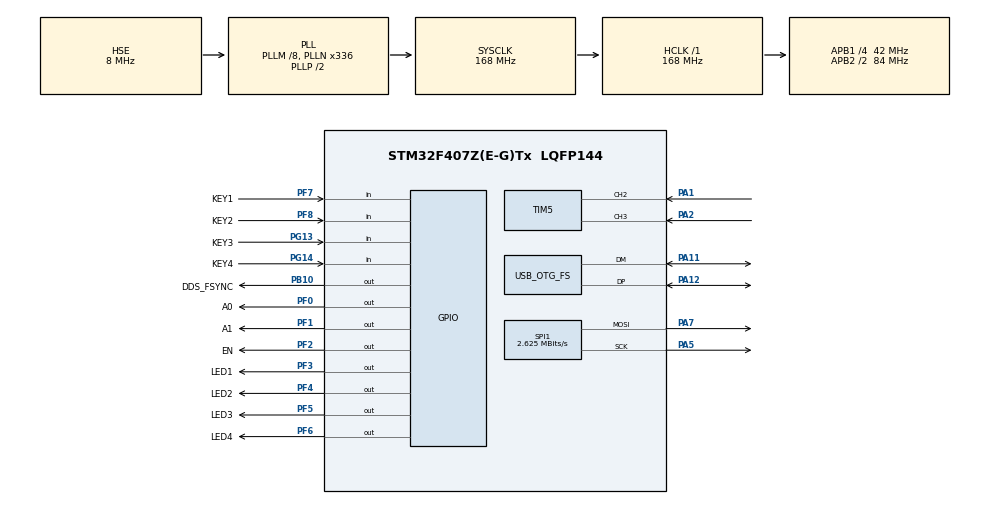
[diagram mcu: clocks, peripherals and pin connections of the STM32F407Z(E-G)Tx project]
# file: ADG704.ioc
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Dma.Request0=TIM5_CH2
Dma.Request1=TIM5_CH3/UP
Dma.TIM5_CH2.0.Direction=DMA_PERIPH_TO_MEMORY
Dma.TIM5_CH2.0.FIFOMode=DMA_FIFOMODE_DISABLE
Dma.TIM5_CH2.0.Instance=DMA1_Stream4
Dma.TIM5_CH2.0.MemDataAlignment=DMA_MDATAALIGN_WORD
Dma.TIM5_CH2.0.MemInc=DMA_MINC_ENABLE
Dma.TIM5_CH2.0.Mode=DMA_NORMAL
Dma.TIM5_CH2.0.PeriphDataAlignment=DMA_PDATAALIGN_WORD
Dma.TIM5_CH2.0.PeriphInc=DMA_PINC_DISABLE
Dma.TIM5_CH2.0.Priority=DMA_PRIORITY_HIGH
Dma.TIM5_CH3/UP.1.Direction=DMA_PERIPH_TO_MEMORY
Dma.TIM5_CH3/UP.1.FIFOMode=DMA_FIFOMODE_DISABLE
Dma.TIM5_CH3/UP.1.Instance=DMA1_Stream0
Dma.TIM5_CH3/UP.1.MemDataAlignment=DMA_MDATAALIGN_WORD
Dma.TIM5_CH3/UP.1.MemInc=DMA_MINC_ENABLE
Dma.TIM5_CH3/UP.1.Mode=DMA_NORMAL
Dma.TIM5_CH3/UP.1.PeriphDataAlignment=DMA_PDATAALIGN_WORD
Dma.TIM5_CH3/UP.1.PeriphInc=DMA_PINC_DISABLE
Dma.TIM5_CH3/UP.1.Priority=DMA_PRIORITY_HIGH
Mcu.Family=STM32F4
Mcu.Name=STM32F407Z(E-G)Tx
Mcu.Package=LQFP144
NVIC.DMA1_Stream0_IRQn=true\:1\:0\:true\:false\:true\:false\:true\:true
NVIC.DMA1_Stream4_IRQn=true\:1\:0\:true\:false\:true\:false\:true\:true
NVIC.PriorityGroup=NVIC_PRIORITYGROUP_4
PA1.Signal=S_TIM5_CH2
PA11.Mode=Device_Only
PA11.Signal=USB_OTG_FS_DM
PA12.Mode=Device_Only
PA12.Signal=USB_OTG_FS_DP
PA13.Signal=SYS_JTMS-SWDIO
PA14.Signal=SYS_JTCK-SWCLK
PA2.Signal=S_TIM5_CH3
PA5.Mode=TX_Only_Simplex_Unidirect_Master
PA5.Signal=SPI1_SCK
PA7.Mode=TX_Only_Simplex_Unidirect_Master
PA7.Signal=SPI1_MOSI
PB10.GPIO_Label=DDS_FSYNC
PB10.GPIO_Speed=GPIO_SPEED_FREQ_HIGH
PB10.PinState=GPIO_PIN_SET
PB10.Signal=GPIO_Output
PF0.GPIO_Label=A0
PF0.GPIO_Speed=GPIO_SPEED_FREQ_LOW
PF0.PinState=GPIO_PIN_RESET
PF0.Signal=GPIO_Output
PF1.GPIO_Label=A1
PF1.Signal=GPIO_Output
PG14.GPIO_Label=KEY4
PG14.Signal=GPIO_Input
PF2.GPIO_Label=EN
PF2.Signal=GPIO_Output
PF3.GPIO_Label=LED1
PF3.Signal=GPIO_Output
PF4.GPIO_Label=LED2
PF4.Signal=GPIO_Output
PF5.GPIO_Label=LED3
PF5.Signal=GPIO_Output
PF6.GPIO_Label=LED4
PF6.Signal=GPIO_Output
PF7.GPIO_Label=KEY1
PF7.GPIO_PuPd=GPIO_NOPULL
PF7.Signal=GPIO_Input
PF8.GPIO_Label=KEY2
PF8.Signal=GPIO_Input
PG13.GPIO_Label=KEY3
PG13.Signal=GPIO_Input
PH0-OSC_IN.Mode=HSE-External-Oscillator
PH0-OSC_IN.Signal=RCC_OSC_IN
PH1-OSC_OUT.Mode=HSE-External-Oscillator
PH1-OSC_OUT.Signal=RCC_OSC_OUT
ProjectManager.HeapSize=0x200
ProjectManager.StackSize=0x400
ProjectManager.TargetToolchain=MDK-ARM V5.32
RCC.48MHZClocksFreq_Value=48000000
RCC.AHBFreq_Value=168000000
RCC.APB1CLKDivider=RCC_HCLK_DIV4
RCC.APB1Freq_Value=42000000
RCC.APB1TimFreq_Value=84000000
RCC.APB2CLKDivider=RCC_HCLK_DIV2
RCC.APB2Freq_Value=84000000
RCC.APB2TimFreq_Value=168000000
RCC.CortexFreq_Value=168000000
RCC.HCLKFreq_Value=168000000
RCC.HSE_VALUE=8000000
RCC.HSI_VALUE=16000000
RCC.LSE_VALUE=32768
RCC.PLLM=8
RCC.PLLN=336
RCC.PLLQ=7
RCC.SYSCLKFreq_VALUE=168000000
RCC.SYSCLKSource=RCC_SYSCLKSOURCE_PLLCLK
RCC.VCOOutputFreq_Value=336000000
SH.S_TIM5_CH2.0=TIM5_CH2,Input_Capture2_from_TI2
SH.S_TIM5_CH3.0=TIM5_CH3,Input_Capture3_from_TI3
SPI1.BaudRatePrescaler=SPI_BAUDRATEPRESCALER_32
SPI1.CLKPolarity=SPI_POLARITY_HIGH
SPI1.CalculateBaudRate=2.625 MBits/s
SPI1.Direction=SPI_DIRECTION_2LINES
SPI1.Mode=SPI_MODE_MASTER
SPI1.VirtualType=VM_MASTER
TIM5.Channel-Input_Capture2_from_TI2=TIM_CHANNEL_2
TIM5.Channel-Input_Capture3_from_TI3=TIM_CHANNEL_3
USB_OTG_FS.VirtualMode=Device_Only
VP_TIM5_VS_ClockSourceINT.Mode=Internal
board=custom

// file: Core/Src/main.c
/* USER CODE BEGIN Header */
/**
  ******************************************************************************
  * @file           : main.c
  * @brief          : Main program body
  ******************************************************************************
  * @attention
  *
  * Copyright (c) 2026 STMicroelectronics.
  * All rights reserved.
  *
  * This software is licensed under terms that can be found in the LICENSE file
  * in the root directory of this software component.
  * If no LICENSE file comes with this software, it is provided AS-IS.
  *
  ******************************************************************************
  */
/* USER CODE END Header */
#include "main.h"

/* USER CODE BEGIN Includes */

#include "amplitude_panel.h"
#include "fsmc.h"
#include "lcd_touch_ui.h"
#include "lissajous_pll.h"
#include "pll_diagnostic_uart.h"

/* USER CODE END Includes */

SPI_HandleTypeDef hspi1;

TIM_HandleTypeDef htim5;
DMA_HandleTypeDef hdma_tim5_ch2;
DMA_HandleTypeDef hdma_tim5_ch3_up;

void SystemClock_Config(void);
static void MX_GPIO_Init(void);
static void MX_DMA_Init(void);
static void MX_TIM5_Init(void);
static void MX_SPI1_Init(void);

int main(void)
{

  /* MCU Configuration--------------------------------------------------------*/

  /* Reset of all peripherals, Initializes the Flash interface and the Systick. */
  HAL_Init();

  /* Configure the system clock */
  SystemClock_Config();

  /* Initialize all configured peripherals */
  MX_GPIO_Init();
  MX_DMA_Init();
  MX_TIM5_Init();
  MX_SPI1_Init();
  MX_FSMC_Init();
  /* USER CODE BEGIN 2 */
  LCDTouchUI_Init(LISSAJOUS_PLL_DEFAULT_MULTIPLIER);
  AmpPanel_Init(AMP_LEVEL_4);
  (void)LissajousPLL_Init(&htim5, &hspi1,
                          LISSAJOUS_PLL_MODE_FREQUENCY_FOLLOW);
  PLL_DiagnosticUart_Init();

  /* USER CODE END 2 */

  /* Infinite loop */
  while (1)
  {

    /* USER CODE BEGIN 3 */
    AmpPanel_Task();
    LissajousPLL_Task();
    LCDTouchUI_Task();
    PLL_DiagnosticUart_Task();
  }
  /* USER CODE END 3 */
}

void SystemClock_Config(void)
{
  RCC_OscInitTypeDef RCC_OscInitStruct = {0};
  RCC_ClkInitTypeDef RCC_ClkInitStruct = {0};

  /** Configure the main internal regulator output voltage
  */
  __HAL_RCC_PWR_CLK_ENABLE();
  __HAL_PWR_VOLTAGESCALING_CONFIG(PWR_REGULATOR_VOLTAGE_SCALE1);

  /** Initializes the RCC Oscillators according to the specified parameters
  * in the RCC_OscInitTypeDef structure.
  */
  RCC_OscInitStruct.OscillatorType = RCC_OSCILLATORTYPE_HSE;
  RCC_OscInitStruct.HSEState = RCC_HSE_ON;
  RCC_OscInitStruct.PLL.PLLState = RCC_PLL_ON;
  RCC_OscInitStruct.PLL.PLLSource = RCC_PLLSOURCE_HSE;
  RCC_OscInitStruct.PLL.PLLM = 8;
  RCC_OscInitStruct.PLL.PLLN = 336;
  RCC_OscInitStruct.PLL.PLLP = RCC_PLLP_DIV2;
  RCC_OscInitStruct.PLL.PLLQ = 7;
  if (HAL_RCC_OscConfig(&RCC_OscInitStruct) != HAL_OK)
  {
    Error_Handler();
  }

  /** Initializes the CPU, AHB and APB buses clocks
  */
  RCC_ClkInitStruct.ClockType = RCC_CLOCKTYPE_HCLK|RCC_CLOCKTYPE_SYSCLK
                              |RCC_CLOCKTYPE_PCLK1|RCC_CLOCKTYPE_PCLK2;
  RCC_ClkInitStruct.SYSCLKSource = RCC_SYSCLKSOURCE_PLLCLK;
  RCC_ClkInitStruct.AHBCLKDivider = RCC_SYSCLK_DIV1;
  RCC_ClkInitStruct.APB1CLKDivider = RCC_HCLK_DIV4;
  RCC_ClkInitStruct.APB2CLKDivider = RCC_HCLK_DIV2;

  if (HAL_RCC_ClockConfig(&RCC_ClkInitStruct, FLASH_LATENCY_5) != HAL_OK)
  {
    Error_Handler();
  }
}

static void MX_SPI1_Init(void)
{

  /* SPI1 parameter configuration*/
  hspi1.Instance = SPI1;
  hspi1.Init.Mode = SPI_MODE_MASTER;
  hspi1.Init.Direction = SPI_DIRECTION_2LINES;
  hspi1.Init.DataSize = SPI_DATASIZE_8BIT;
  hspi1.Init.CLKPolarity = SPI_POLARITY_HIGH;
  hspi1.Init.CLKPhase = SPI_PHASE_1EDGE;
  hspi1.Init.NSS = SPI_NSS_SOFT;
  hspi1.Init.BaudRatePrescaler = SPI_BAUDRATEPRESCALER_32;
  hspi1.Init.FirstBit = SPI_FIRSTBIT_MSB;
  hspi1.Init.TIMode = SPI_TIMODE_DISABLE;
  hspi1.Init.CRCCalculation = SPI_CRCCALCULATION_DISABLE;
  hspi1.Init.CRCPolynomial = 10;
  if (HAL_SPI_Init(&hspi1) != HAL_OK)
  {
    Error_Handler();
  }

}

static void MX_TIM5_Init(void)
{

  TIM_ClockConfigTypeDef sClockSourceConfig = {0};
  TIM_MasterConfigTypeDef sMasterConfig = {0};
  TIM_IC_InitTypeDef sConfigIC = {0};

  htim5.Instance = TIM5;
  htim5.Init.Prescaler = 0;
  htim5.Init.CounterMode = TIM_COUNTERMODE_UP;
  htim5.Init.Period = 4294967295;
  htim5.Init.ClockDivision = TIM_CLOCKDIVISION_DIV1;
  htim5.Init.AutoReloadPreload = TIM_AUTORELOAD_PRELOAD_DISABLE;
  if (HAL_TIM_Base_Init(&htim5) != HAL_OK)
  {
    Error_Handler();
  }
  sClockSourceConfig.ClockSource = TIM_CLOCKSOURCE_INTERNAL;
  if (HAL_TIM_ConfigClockSource(&htim5, &sClockSourceConfig) != HAL_OK)
  {
    Error_Handler();
  }
  if (HAL_TIM_IC_Init(&htim5) != HAL_OK)
  {
    Error_Handler();
  }
  sMasterConfig.MasterOutputTrigger = TIM_TRGO_RESET;
  sMasterConfig.MasterSlaveMode = TIM_MASTERSLAVEMODE_DISABLE;
  if (HAL_TIMEx_MasterConfigSynchronization(&htim5, &sMasterConfig) != HAL_OK)
  {
    Error_Handler();
  }
  sConfigIC.ICPolarity = TIM_INPUTCHANNELPOLARITY_RISING;
  sConfigIC.ICSelection = TIM_ICSELECTION_DIRECTTI;
  sConfigIC.ICPrescaler = TIM_ICPSC_DIV8;
  sConfigIC.ICFilter = 8;
  if (HAL_TIM_IC_ConfigChannel(&htim5, &sConfigIC, TIM_CHANNEL_2) != HAL_OK)
  {
    Error_Handler();
  }
  if (HAL_TIM_IC_ConfigChannel(&htim5, &sConfigIC, TIM_CHANNEL_3) != HAL_OK)
  {
    Error_Handler();
  }

}

static void MX_DMA_Init(void)
{

  /* DMA controller clock enable */
  __HAL_RCC_DMA1_CLK_ENABLE();

  /* DMA interrupt init */
  /* DMA1_Stream0_IRQn interrupt configuration */
  HAL_NVIC_SetPriority(DMA1_Stream0_IRQn, 1, 0);
  HAL_NVIC_EnableIRQ(DMA1_Stream0_IRQn);
  /* DMA1_Stream4_IRQn interrupt configuration */
  HAL_NVIC_SetPriority(DMA1_Stream4_IRQn, 1, 0);
  HAL_NVIC_EnableIRQ(DMA1_Stream4_IRQn);

}

static void MX_GPIO_Init(void)
{
  GPIO_InitTypeDef GPIO_InitStruct = {0};

  /* GPIO Ports Clock Enable */
  __HAL_RCC_GPIOF_CLK_ENABLE();
  __HAL_RCC_GPIOH_CLK_ENABLE();
  __HAL_RCC_GPIOA_CLK_ENABLE();
  __HAL_RCC_GPIOB_CLK_ENABLE();
  __HAL_RCC_GPIOG_CLK_ENABLE();

  /*Configure GPIO pin Output Level */
  HAL_GPIO_WritePin(GPIOF, A0_Pin|A1_Pin|EN_Pin|LED1_Pin
                          |LED2_Pin|LED3_Pin|LED4_Pin, GPIO_PIN_RESET);

  /*Configure GPIO pin Output Level */
  HAL_GPIO_WritePin(DDS_FSYNC_GPIO_Port, DDS_FSYNC_Pin, GPIO_PIN_SET);
  HAL_GPIO_WritePin(GPIOB, GPIO_PIN_15, GPIO_PIN_RESET);

  /*Configure GPIO pins : A0_Pin A1_Pin EN_Pin LED1_Pin
                           LED2_Pin LED3_Pin LED4_Pin */
  GPIO_InitStruct.Pin = A0_Pin|A1_Pin|EN_Pin|LED1_Pin
                          |LED2_Pin|LED3_Pin|LED4_Pin;
  GPIO_InitStruct.Mode = GPIO_MODE_OUTPUT_PP;
  GPIO_InitStruct.Pull = GPIO_NOPULL;
  GPIO_InitStruct.Speed = GPIO_SPEED_FREQ_LOW;
  HAL_GPIO_Init(GPIOF, &GPIO_InitStruct);

  /*Configure GPIO pins : KEY1_Pin KEY2_Pin */
  GPIO_InitStruct.Pin = KEY1_Pin|KEY2_Pin;
  GPIO_InitStruct.Mode = GPIO_MODE_INPUT;
  GPIO_InitStruct.Pull = GPIO_NOPULL;
  HAL_GPIO_Init(GPIOF, &GPIO_InitStruct);

  /*Configure GPIO pins : KEY3_Pin KEY4_Pin */
  GPIO_InitStruct.Pin = KEY3_Pin|KEY4_Pin;
  GPIO_InitStruct.Mode = GPIO_MODE_INPUT;
  GPIO_InitStruct.Pull = GPIO_NOPULL;
  HAL_GPIO_Init(GPIOG, &GPIO_InitStruct);

  /*Configure GPIO pin : DDS_FSYNC_Pin */
  GPIO_InitStruct.Pin = DDS_FSYNC_Pin;
  GPIO_InitStruct.Mode = GPIO_MODE_OUTPUT_PP;
  GPIO_InitStruct.Pull = GPIO_NOPULL;
  GPIO_InitStruct.Speed = GPIO_SPEED_FREQ_HIGH;
  HAL_GPIO_Init(DDS_FSYNC_GPIO_Port, &GPIO_InitStruct);

  /* LCD backlight (TFT.ioc: PB15). */
  GPIO_InitStruct.Pin = GPIO_PIN_15;
  GPIO_InitStruct.Mode = GPIO_MODE_OUTPUT_PP;
  GPIO_InitStruct.Pull = GPIO_NOPULL;
  GPIO_InitStruct.Speed = GPIO_SPEED_FREQ_LOW;
  HAL_GPIO_Init(GPIOB, &GPIO_InitStruct);
}

void Error_Handler(void)
{
  __disable_irq();
  while (1)
  {
  }
}
